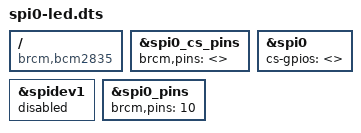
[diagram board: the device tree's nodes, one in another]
// This is a custom device tree overlay for the spi0 peripheral on the
// Raspberry Pi 4. It will configure only the spi0 mosi pin
// (The other spi0 pins will not be driven by the spi0 peripheral,
// and can be used for other functions). This is to be used with
// the Blue Robotics Navigator autopilot hat, where the RGB
// 'neopixel' led data pin is connected to the spi0 mosi pin on the
// Raspberry Pi 4.

/dts-v1/;
/plugin/;


/ {
    compatible = "brcm,bcm2835";

    fragment@0 {
        target = <&spi0_cs_pins>;
        frag0: __overlay__ {
            brcm,pins = <>;
        };
    };

    fragment@1 {
        target = <&spi0>;
        frag1: __overlay__ {
            cs-gpios = <>;
            status = "okay";
        };
    };

    fragment@2 {
        target = <&spidev1>;
        __overlay__ {
            status = "disabled";
        };
    };

    fragment@3 {
        target = <&spi0_pins>;
        __overlay__ {
            brcm,pins = <10>;
        };
    };
};
